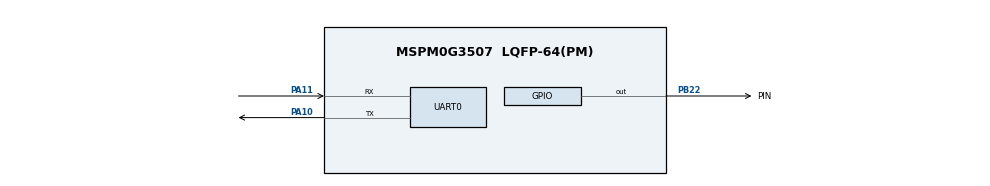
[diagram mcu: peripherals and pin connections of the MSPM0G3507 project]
/**
 * control.syscfg — 外设配置唯一机器事实源（PLAN.md §一）
 *
 * P2 时间基准（保留 P1 的正式时钟和板级引脚）：
 *   - **正式时钟基线 80MHz**（HFXT 40MHz + SYSPLL，TI 官方路径；PB22/UART0/SWD 功能不变）
 *   - PB22 板载 LED（GPIO 输出，初始低 = 熄灭）
 *   - UART0 @ PA10/PA11（板载 CH340 → PC 串口，SERIAL_PORT 由 scripts/env.local.ps1 指定，115200 8N1）——文本调试日志
 *   - DEBUGSS（SWD: PA19/PA20，XDS110 调试）
 *
 *   - TIMG12：1ms ZERO 中断，BSP 显式启动；无 PWM/I2C/UART1。
 * 禁改生成文件（firmware/Debug/syscfg/*）；改这里之后重新生成。
 *
 * @cliArgs --device "MSPM0G3507" --package "LQFP-64(PM)" --product "mspm0_sdk@2.10.00.04"
 * @versions {"tool":"1.27.1+4634"}
 */
const SYSCTL = scripting.addModule("/ti/driverlib/SYSCTL");
const Board  = scripting.addModule("/ti/driverlib/Board", {}, false);

/* ---- 时钟树：80MHz 正式基线（HFXT 40MHz → SYSPLL → MCLK 80MHz；UDIV/2 给 ULPCLK 40MHz）----
 * 参考路径已在天猛星例程（TB6612/SG90 例程的 empty.syscfg）与本机 SysConfig 1.27.1 验证。
 * HFXT warning（Solution may have changed）为已知提示，消除项见 docs/ERRATA_CHECKLIST。
 *
 * SYSPLL_ERR_01（SLAZ742H）：SYSPLL 使能时可能锁错频。SDK 2.10 SysConfig 对该勘误的 FCC 校验
 * workaround 默认开启（SYSCTL 时钟选项 enableWorkaround_SYSPLL_ERR_01 默认 true，
 * isdeviceAffected_SYSPLL_ERR_01() 对全部设备返回 true），生成 ti_msp_dl_config.c 自动包含
 * FCC 测频 + 比例界检查 + 失败 toggle 重锁循环；本项目未覆盖该 WEAK 函数、不改生成文件。
 * 见 docs/ERRATA_CHECKLIST.md。 */
SYSCTL.clockTreeEn = true;

const udiv = system.clockTree["UDIV"];
udiv.divideValue = 2;                       /* ULPCLK = MCLK/2 = 40MHz（UART 时钟源域） */

const exhfmux = system.clockTree["EXHFMUX"];
exhfmux.inputSelect = "EXHFMUX_XTAL";       /* HFCLK 源 = HFXT 晶振 */

const syspllmux = system.clockTree["SYSPLLMUX"];
syspllmux.inputSelect = "zSYSPLLMUX_HFCLK"; /* SYSPLL 输入 = HFCLK(40MHz) */

const hsclkmux = system.clockTree["HSCLKMUX"];
hsclkmux.inputSelect = "HSCLKMUX_SYSPLL2X"; /* MCLK = SYSPLL2X 输出 = 80MHz */

const hfxt = system.clockTree["HFXT"];
hfxt.inputFreq    = 40;                     /* 天猛星板载 40MHz 晶振（PA5/PA6） */
hfxt.enable       = true;
hfxt.HFCLKMonitor = true;                   /* HFCLK 故障监测（Kconfig：失效自动切 SYSOSC） */
hfxt.HFXTStartup  = 20;                     /* 启动等待时间（us 级经验值，例程同款） */

/* PB22 板载 LED：GPIO 输出，初始低（熄灭）——P1 心跳灯 */
const LED = scripting.addModule("/ti/driverlib/GPIO", {}, false);
const LED1 = LED.addInstance();
LED1.$name                          = "LED";
LED1.associatedPins.create(1);
LED1.associatedPins[0].$name        = "PIN";
LED1.associatedPins[0].ioStructure  = "SD";
LED1.associatedPins[0].assignedPort = "PORTB";
LED1.associatedPins[0].assignedPin  = "22";
LED1.associatedPins[0].pin.$assign  = "PB22";
LED1.associatedPins[0].initialValue = "CLEARED"; /* 上电熄灭（安全默认） */

/* UART0 = 文本调试日志（板上 CH340 → PC；FIXED_BOARD_FUNCTION，见 PLAN.md §二） */
const UART = scripting.addModule("/ti/driverlib/UART", {}, false);
const UART0 = UART.addInstance();
UART0.$name                        = "DEBUG_UART";
UART0.targetBaudRate               = 115200;
UART0.peripheral.$assign           = "UART0";
UART0.peripheral.txPin.$assign     = "PA10";
UART0.peripheral.rxPin.$assign     = "PA11";
UART0.txPinConfig.$name            = "ti_driverlib_gpio_debug_tx";
UART0.txPinConfig.enableConfig     = true;
UART0.txPinConfig.internalResistor = "PULL_UP";
UART0.rxPinConfig.$name            = "ti_driverlib_gpio_debug_rx";
UART0.rxPinConfig.enableConfig     = true;
UART0.rxPinConfig.internalResistor = "PULL_UP";

/* ---- P2：TIMG12 = 1ms 系统节拍（时间基准；PLAN.md §三/§六）----
 * 集中式 ISR（bsp/interrupts.c）只做 tick++；BUSCLK 80MHz / 80000 = 1kHz。
 * timerStartTimer=false：初始化后不自动启动，由 timebase BSP 在 IRQ 就绪后显式启动。 */
const TIMER = scripting.addModule("/ti/driverlib/TIMER", {}, false);
const TICK = TIMER.addInstance();
TICK.$name          = "SYS_TICK";
TICK.timerMode      = "PERIODIC";
TICK.timerPeriod    = "1 ms";
TICK.peripheral.$assign = "TIMG12";
TICK.interrupts     = ["ZERO"];
TICK.timerStartTimer = false;

/* SWD 调试口（XDS110；FIXED_BOARD_FUNCTION）
 * 注意：80MHz 时钟树模式下 SYSCTL.peripheral 为 undefined（skill 实测笔记），
 * 其 pinmux 建议应挂在 clockTree["HFXT"].peripheral 上（见 hfxt.peripheral.$suggestSolution）。 */
Board.peripheral.$suggestSolution          = "DEBUGSS";
Board.peripheral.swclkPin.$suggestSolution = "PA20";
Board.peripheral.swdioPin.$suggestSolution = "PA19";
hfxt.peripheral.$suggestSolution           = "SYSCTL";
